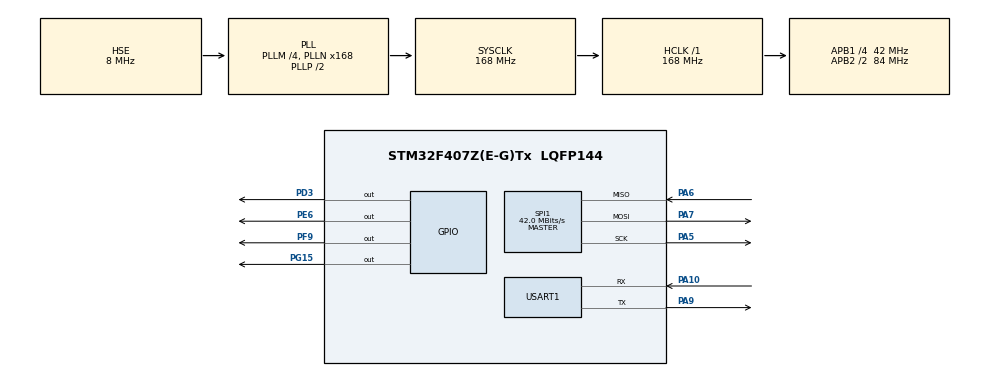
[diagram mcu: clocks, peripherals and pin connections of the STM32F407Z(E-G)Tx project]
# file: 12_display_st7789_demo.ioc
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Dma.Request0=SPI1_RX
Dma.Request1=SPI1_TX
Dma.SPI1_RX.0.Direction=DMA_PERIPH_TO_MEMORY
Dma.SPI1_RX.0.FIFOMode=DMA_FIFOMODE_DISABLE
Dma.SPI1_RX.0.Instance=DMA2_Stream0
Dma.SPI1_RX.0.MemDataAlignment=DMA_MDATAALIGN_BYTE
Dma.SPI1_RX.0.MemInc=DMA_MINC_ENABLE
Dma.SPI1_RX.0.Mode=DMA_NORMAL
Dma.SPI1_RX.0.PeriphDataAlignment=DMA_PDATAALIGN_BYTE
Dma.SPI1_RX.0.PeriphInc=DMA_PINC_DISABLE
Dma.SPI1_RX.0.Priority=DMA_PRIORITY_LOW
Dma.SPI1_TX.1.Direction=DMA_MEMORY_TO_PERIPH
Dma.SPI1_TX.1.FIFOMode=DMA_FIFOMODE_DISABLE
Dma.SPI1_TX.1.Instance=DMA2_Stream3
Dma.SPI1_TX.1.MemDataAlignment=DMA_MDATAALIGN_BYTE
Dma.SPI1_TX.1.MemInc=DMA_MINC_ENABLE
Dma.SPI1_TX.1.Mode=DMA_NORMAL
Dma.SPI1_TX.1.PeriphDataAlignment=DMA_PDATAALIGN_BYTE
Dma.SPI1_TX.1.PeriphInc=DMA_PINC_DISABLE
Dma.SPI1_TX.1.Priority=DMA_PRIORITY_LOW
Mcu.Family=STM32F4
Mcu.Name=STM32F407Z(E-G)Tx
Mcu.Package=LQFP144
NVIC.DMA2_Stream0_IRQn=true\:0\:0\:false\:false\:true\:false\:true\:true
NVIC.DMA2_Stream3_IRQn=true\:0\:0\:false\:false\:true\:false\:true\:true
NVIC.PriorityGroup=NVIC_PRIORITYGROUP_4
NVIC.SPI1_IRQn=true\:0\:0\:false\:false\:true\:true\:true\:true
NVIC.USART1_IRQn=true\:0\:0\:false\:false\:true\:true\:true\:true
PA10.Mode=Asynchronous
PA10.Signal=USART1_RX
PA13.Mode=Serial_Wire
PA13.Signal=SYS_JTMS-SWDIO
PA14.Mode=Serial_Wire
PA14.Signal=SYS_JTCK-SWCLK
PA5.Mode=Full_Duplex_Master
PA5.Signal=SPI1_SCK
PA6.Mode=Full_Duplex_Master
PA6.Signal=SPI1_MISO
PA7.Mode=Full_Duplex_Master
PA7.Signal=SPI1_MOSI
PA9.Mode=Asynchronous
PA9.Signal=USART1_TX
PC14-OSC32_IN.Mode=LSE-External-Oscillator
PC14-OSC32_IN.Signal=RCC_OSC32_IN
PC15-OSC32_OUT.Mode=LSE-External-Oscillator
PC15-OSC32_OUT.Signal=RCC_OSC32_OUT
PD3.PinState=GPIO_PIN_SET
PD3.Signal=GPIO_Output
PE6.PinState=GPIO_PIN_SET
PE6.Signal=GPIO_Output
PF9.PinState=GPIO_PIN_SET
PF9.Signal=GPIO_Output
PG15.PinState=GPIO_PIN_SET
PG15.Signal=GPIO_Output
PH0-OSC_IN.Mode=HSE-External-Oscillator
PH0-OSC_IN.Signal=RCC_OSC_IN
PH1-OSC_OUT.Mode=HSE-External-Oscillator
PH1-OSC_OUT.Signal=RCC_OSC_OUT
ProjectManager.HeapSize=0x200
ProjectManager.StackSize=0x400
ProjectManager.TargetToolchain=MDK-ARM V5.32
RCC.48MHZClocksFreq_Value=84000000
RCC.AHBFreq_Value=168000000
RCC.APB1CLKDivider=RCC_HCLK_DIV4
RCC.APB1Freq_Value=42000000
RCC.APB1TimFreq_Value=84000000
RCC.APB2CLKDivider=RCC_HCLK_DIV2
RCC.APB2Freq_Value=84000000
RCC.APB2TimFreq_Value=168000000
RCC.CortexFreq_Value=168000000
RCC.HCLKFreq_Value=168000000
RCC.HSE_VALUE=8000000
RCC.HSI_VALUE=16000000
RCC.PLLM=4
RCC.PLLN=168
RCC.PLLSourceVirtual=RCC_PLLSOURCE_HSE
RCC.SYSCLKFreq_VALUE=168000000
RCC.SYSCLKSource=RCC_SYSCLKSOURCE_PLLCLK
RCC.VCOOutputFreq_Value=336000000
SPI1.CalculateBaudRate=42.0 MBits/s
SPI1.Direction=SPI_DIRECTION_2LINES
SPI1.Mode=SPI_MODE_MASTER
SPI1.VirtualType=VM_MASTER
USART1.VirtualMode=VM_ASYNC
board=custom

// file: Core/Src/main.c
/* USER CODE BEGIN Header */
/**
  ******************************************************************************
  * @file           : main.c
  * @brief          : Main program body
  ******************************************************************************
  * @attention
  *
  * Copyright (c) 2023 STMicroelectronics.
  * All rights reserved.
  *
  * This software is licensed under terms that can be found in the LICENSE file
  * in the root directory of this software component.
  * If no LICENSE file comes with this software, it is provided AS-IS.
  *
  ******************************************************************************
  */
/* USER CODE END Header */
#include "main.h"
#include "dma.h"
#include "spi.h"
#include "usart.h"
#include "gpio.h"

void SystemClock_Config(void);

/* USER CODE BEGIN 0 */
extern void app_st7789_test(void);
/* USER CODE END 0 */

int main(void)
{

  /* MCU Configuration--------------------------------------------------------*/

  /* Reset of all peripherals, Initializes the Flash interface and the Systick. */
  HAL_Init();

  /* Configure the system clock */
  SystemClock_Config();

  /* Initialize all configured peripherals */
  MX_GPIO_Init();
  MX_DMA_Init();
  MX_SPI1_Init();
  MX_USART1_UART_Init();
  /* USER CODE BEGIN 2 */
   app_st7789_test();
  /* USER CODE END 2 */

  /* Infinite loop */
  while (1)
  {

  }
}

void SystemClock_Config(void)
{
  RCC_OscInitTypeDef RCC_OscInitStruct = {0};
  RCC_ClkInitTypeDef RCC_ClkInitStruct = {0};

  /** Configure the main internal regulator output voltage
  */
  __HAL_RCC_PWR_CLK_ENABLE();
  __HAL_PWR_VOLTAGESCALING_CONFIG(PWR_REGULATOR_VOLTAGE_SCALE1);

  /** Initializes the RCC Oscillators according to the specified parameters
  * in the RCC_OscInitTypeDef structure.
  */
  RCC_OscInitStruct.OscillatorType = RCC_OSCILLATORTYPE_HSE;
  RCC_OscInitStruct.HSEState = RCC_HSE_ON;
  RCC_OscInitStruct.PLL.PLLState = RCC_PLL_ON;
  RCC_OscInitStruct.PLL.PLLSource = RCC_PLLSOURCE_HSE;
  RCC_OscInitStruct.PLL.PLLM = 4;
  RCC_OscInitStruct.PLL.PLLN = 168;
  RCC_OscInitStruct.PLL.PLLP = RCC_PLLP_DIV2;
  RCC_OscInitStruct.PLL.PLLQ = 4;
  if (HAL_RCC_OscConfig(&RCC_OscInitStruct) != HAL_OK)
  {
    Error_Handler();
  }

  /** Initializes the CPU, AHB and APB buses clocks
  */
  RCC_ClkInitStruct.ClockType = RCC_CLOCKTYPE_HCLK|RCC_CLOCKTYPE_SYSCLK
                              |RCC_CLOCKTYPE_PCLK1|RCC_CLOCKTYPE_PCLK2;
  RCC_ClkInitStruct.SYSCLKSource = RCC_SYSCLKSOURCE_PLLCLK;
  RCC_ClkInitStruct.AHBCLKDivider = RCC_SYSCLK_DIV1;
  RCC_ClkInitStruct.APB1CLKDivider = RCC_HCLK_DIV4;
  RCC_ClkInitStruct.APB2CLKDivider = RCC_HCLK_DIV2;

  if (HAL_RCC_ClockConfig(&RCC_ClkInitStruct, FLASH_LATENCY_5) != HAL_OK)
  {
    Error_Handler();
  }
}

void Error_Handler(void)
{
  __disable_irq();
  while (1)
  {
  }
}
